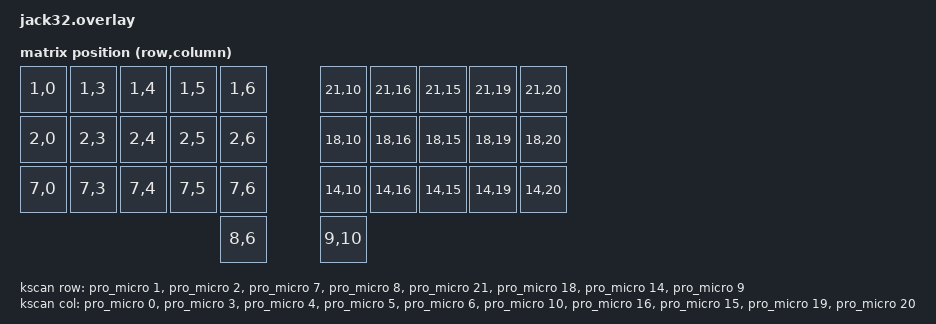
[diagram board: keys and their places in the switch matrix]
// This file was generated from a template. Edit it to match your keyboard.
// See https://zmk.dev/docs/development/new-shield for more instructions.

#include <dt-bindings/zmk/matrix_transform.h>

/ {
    chosen {
        zmk,kscan = &kscan;
        zmk,matrix_transform = &default_transform;
    };

    kscan: kscan {
        // If the hardware does not use a switch matrix, change this to the
        // appropriate driver and update the properties below to match.
        // See https://zmk.dev/docs/config/kscan for supported key scan drivers.
        compatible = "zmk,kscan-gpio-matrix";
        // Set this to "col2row" or "row2col" to match the hardware. If using
        // "row2col", change the col-gpios to (GPIO_ACTIVE_HIGH | GPIO_PULL_DOWN)
        // and the row-gpios to GPIO_ACTIVE_HIGH.
        diode-direction = "row2col";
        wakeup-source;

        // Replace these comments with the GPIO pins in the matrix.
        // See https://zmk.dev/docs/development/new-shield#shield-overlays
        col-gpios = <&pro_micro 0 (GPIO_ACTIVE_HIGH | GPIO_PULL_DOWN)>,
                    <&pro_micro 3 (GPIO_ACTIVE_HIGH | GPIO_PULL_DOWN)>,
                    <&pro_micro 4 (GPIO_ACTIVE_HIGH | GPIO_PULL_DOWN)>,
                    <&pro_micro 5 (GPIO_ACTIVE_HIGH | GPIO_PULL_DOWN)>,
                    <&pro_micro 6 (GPIO_ACTIVE_HIGH | GPIO_PULL_DOWN)>,
                    <&pro_micro 10 (GPIO_ACTIVE_HIGH | GPIO_PULL_DOWN)>,
                    <&pro_micro 16 (GPIO_ACTIVE_HIGH | GPIO_PULL_DOWN)>,
                    <&pro_micro 15 (GPIO_ACTIVE_HIGH | GPIO_PULL_DOWN)>,
                    <&pro_micro 19 (GPIO_ACTIVE_HIGH | GPIO_PULL_DOWN)>,
                    <&pro_micro 20 (GPIO_ACTIVE_HIGH | GPIO_PULL_DOWN)>;

        row-gpios = <&pro_micro 1 GPIO_ACTIVE_HIGH>,
                    <&pro_micro 2 GPIO_ACTIVE_HIGH>,
                    <&pro_micro 7 GPIO_ACTIVE_HIGH>,
                    <&pro_micro 8 GPIO_ACTIVE_HIGH>,
                    <&pro_micro 21 GPIO_ACTIVE_HIGH>,
                    <&pro_micro 18 GPIO_ACTIVE_HIGH>,
                    <&pro_micro 14 GPIO_ACTIVE_HIGH>,
                    <&pro_micro 9 GPIO_ACTIVE_HIGH>;
    };

    default_transform: default_transform {
        // See https://zmk.dev/docs/development/new-shield#optional-matrix-transform
        // for how to configure this
        compatible = "zmk,matrix-transform";
        rows = <8>;
        columns = <10>;

        map = <
            RC(1,0) RC(1,3) RC(1,4) RC(1,5) RC(1,6) RC(21,10) RC(21,16) RC(21,15) RC(21,19) RC(21,20)
            RC(2,0) RC(2,3) RC(2,4) RC(2,5) RC(2,6) RC(18,10) RC(18,16) RC(18,15) RC(18,19) RC(18,20)       
            RC(7,0) RC(7,3) RC(7,4) RC(7,5) RC(7,6) RC(14,10) RC(14,16) RC(14,15) RC(14,19) RC(14,20)       
                                            RC(8,6) RC(9,10)    
        >;

    };
};
